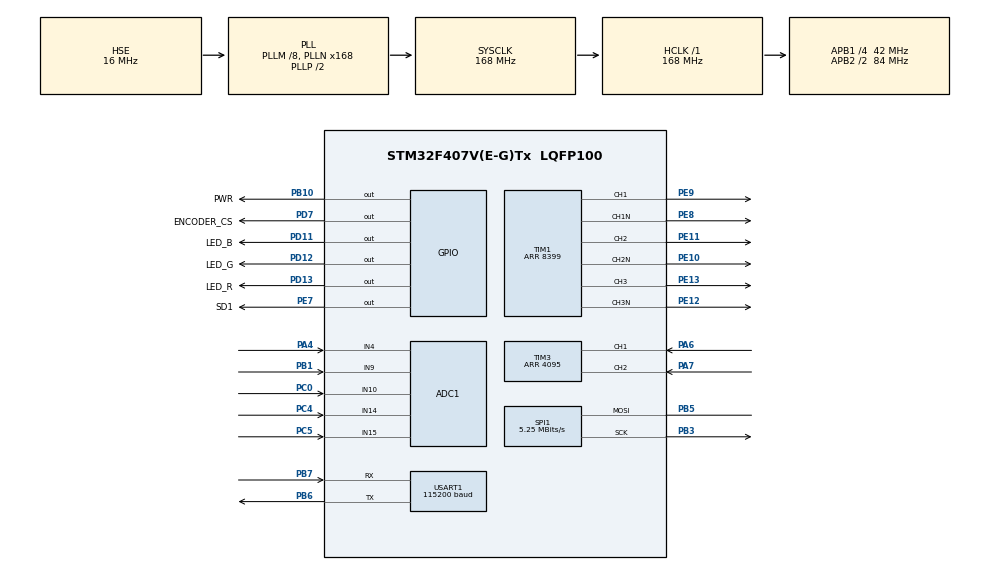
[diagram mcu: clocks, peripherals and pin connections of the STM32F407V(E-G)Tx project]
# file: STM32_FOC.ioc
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ADC1.Channel-0\#ChannelRegularConversion=ADC_CHANNEL_15
ADC1.Channel-1\#ChannelRegularConversion=ADC_CHANNEL_14
ADC1.Channel-2\#ChannelRegularConversion=ADC_CHANNEL_10
ADC1.Channel-3\#ChannelRegularConversion=ADC_CHANNEL_9
ADC1.Channel-4\#ChannelRegularConversion=ADC_CHANNEL_4
ADC1.ContinuousConvMode=ENABLE
ADC1.DMAContinuousRequests=ENABLE
ADC1.NbrOfConversion=5
ADC1.NbrOfConversionFlag=1
ADC1.Rank-0\#ChannelRegularConversion=1
ADC1.Rank-1\#ChannelRegularConversion=2
ADC1.Rank-2\#ChannelRegularConversion=3
ADC1.Rank-3\#ChannelRegularConversion=4
ADC1.Rank-4\#ChannelRegularConversion=5
ADC1.SamplingTime-0\#ChannelRegularConversion=ADC_SAMPLETIME_3CYCLES
ADC1.SamplingTime-1\#ChannelRegularConversion=ADC_SAMPLETIME_3CYCLES
ADC1.SamplingTime-2\#ChannelRegularConversion=ADC_SAMPLETIME_3CYCLES
ADC1.SamplingTime-3\#ChannelRegularConversion=ADC_SAMPLETIME_3CYCLES
ADC1.SamplingTime-4\#ChannelRegularConversion=ADC_SAMPLETIME_3CYCLES
ADC1.ScanConvMode=ENABLE
ADC1.master=1
Dma.ADC1.0.Direction=DMA_PERIPH_TO_MEMORY
Dma.ADC1.0.FIFOMode=DMA_FIFOMODE_DISABLE
Dma.ADC1.0.Instance=DMA2_Stream0
Dma.ADC1.0.MemDataAlignment=DMA_MDATAALIGN_HALFWORD
Dma.ADC1.0.MemInc=DMA_MINC_ENABLE
Dma.ADC1.0.Mode=DMA_CIRCULAR
Dma.ADC1.0.PeriphDataAlignment=DMA_PDATAALIGN_HALFWORD
Dma.ADC1.0.PeriphInc=DMA_PINC_DISABLE
Dma.ADC1.0.Priority=DMA_PRIORITY_HIGH
Dma.Request0=ADC1
Mcu.Family=STM32F4
Mcu.Name=STM32F407V(E-G)Tx
Mcu.Package=LQFP100
NVIC.PriorityGroup=NVIC_PRIORITYGROUP_4
NVIC.TIM1_UP_TIM10_IRQn=true\:0\:0\:false\:false\:true\:true\:true\:true
NVIC.TIM4_IRQn=true\:2\:0\:true\:false\:true\:true\:true\:true
NVIC.USART1_IRQn=true\:0\:0\:false\:false\:true\:true\:true\:true
PA13.Mode=Serial_Wire
PA13.Signal=SYS_JTMS-SWDIO
PA14.Mode=Serial_Wire
PA14.Signal=SYS_JTCK-SWCLK
PA4.Signal=ADCx_IN4
PA6.Signal=S_TIM3_CH1
PA7.Signal=S_TIM3_CH2
PB1.Signal=ADCx_IN9
PB10.GPIO_Label=PWR
PB10.PinState=GPIO_PIN_SET
PB10.Signal=GPIO_Output
PB3.Mode=Simplex_Bidirectional_Master
PB3.Signal=SPI1_SCK
PB4.Signal=SPI1_MISO
PB5.Mode=Simplex_Bidirectional_Master
PB5.Signal=SPI1_MOSI
PB6.Mode=Asynchronous
PB6.Signal=USART1_TX
PB7.Mode=Asynchronous
PB7.Signal=USART1_RX
PC0.Signal=ADCx_IN10
PC4.Signal=ADCx_IN14
PC5.Signal=ADCx_IN15
PD11.GPIO_Label=LED_B
PD11.PinState=GPIO_PIN_SET
PD11.Signal=GPIO_Output
PD12.GPIO_Label=LED_G
PD12.PinState=GPIO_PIN_SET
PD12.Signal=GPIO_Output
PD13.GPIO_Label=LED_R
PD13.PinState=GPIO_PIN_SET
PD13.Signal=GPIO_Output
PD7.GPIO_Label=ENCODER_CS
PD7.PinState=GPIO_PIN_SET
PD7.Signal=GPIO_Output
PE10.Mode=PWM Generation2 CH2 CH2N
PE10.Signal=TIM1_CH2N
PE11.Signal=S_TIM1_CH2
PE12.Mode=PWM Generation3 CH3 CH3N
PE12.Signal=TIM1_CH3N
PE13.Signal=S_TIM1_CH3
PE7.GPIO_Label=SD1
PE7.GPIO_Speed=GPIO_SPEED_FREQ_VERY_HIGH
PE7.Signal=GPIO_Output
PE8.Mode=PWM Generation1 CH1 CH1N
PE8.Signal=TIM1_CH1N
PE9.Signal=S_TIM1_CH1
PH0-OSC_IN.Mode=HSE-External-Oscillator
PH0-OSC_IN.Signal=RCC_OSC_IN
PH1-OSC_OUT.Mode=HSE-External-Oscillator
PH1-OSC_OUT.Signal=RCC_OSC_OUT
ProjectManager.HeapSize=0x200
ProjectManager.StackSize=0x400
ProjectManager.TargetToolchain=MDK-ARM V5.32
RCC.48MHZClocksFreq_Value=84000000
RCC.AHBFreq_Value=168000000
RCC.APB1CLKDivider=RCC_HCLK_DIV4
RCC.APB1Freq_Value=42000000
RCC.APB1TimFreq_Value=84000000
RCC.APB2CLKDivider=RCC_HCLK_DIV2
RCC.APB2Freq_Value=84000000
RCC.APB2TimFreq_Value=168000000
RCC.CortexFreq_Value=168000000
RCC.HCLKFreq_Value=168000000
RCC.HSE_VALUE=16000000
RCC.HSI_VALUE=16000000
RCC.LSE_VALUE=32768
RCC.PLLM=8
RCC.PLLN=168
RCC.PLLSourceVirtual=RCC_PLLSOURCE_HSE
RCC.SYSCLKFreq_VALUE=168000000
RCC.SYSCLKSource=RCC_SYSCLKSOURCE_PLLCLK
RCC.VCOOutputFreq_Value=336000000
SH.ADCx_IN10.0=ADC1_IN10,IN10
SH.ADCx_IN14.0=ADC1_IN14,IN14
SH.ADCx_IN15.0=ADC1_IN15,IN15
SH.ADCx_IN4.0=ADC1_IN4,IN4
SH.ADCx_IN9.0=ADC1_IN9,IN9
SH.S_TIM1_CH1.0=TIM1_CH1,PWM Generation1 CH1 CH1N
SH.S_TIM1_CH2.0=TIM1_CH2,PWM Generation2 CH2 CH2N
SH.S_TIM1_CH3.0=TIM1_CH3,PWM Generation3 CH3 CH3N
SH.S_TIM3_CH1.0=TIM3_CH1,Encoder_Interface
SH.S_TIM3_CH2.0=TIM3_CH2,Encoder_Interface
SPI1.BaudRatePrescaler=SPI_BAUDRATEPRESCALER_16
SPI1.CLKPhase=SPI_PHASE_2EDGE
SPI1.CRCCalculation=SPI_CRCCALCULATION_DISABLE
SPI1.CalculateBaudRate=5.25 MBits/s
SPI1.Direction=SPI_DIRECTION_1LINE
SPI1.Mode=SPI_MODE_MASTER
SPI1.VirtualType=VM_MASTER
TIM1.AutoReloadPreload=TIM_AUTORELOAD_PRELOAD_ENABLE
TIM1.AutomaticOutput=TIM_AUTOMATICOUTPUT_ENABLE
TIM1.Channel-PWM\ Generation1\ CH1\ CH1N=TIM_CHANNEL_1
TIM1.Channel-PWM\ Generation2\ CH2\ CH2N=TIM_CHANNEL_2
TIM1.Channel-PWM\ Generation3\ CH3\ CH3N=TIM_CHANNEL_3
TIM1.CounterMode=TIM_COUNTERMODE_CENTERALIGNED1
TIM1.DeadTime=100
TIM1.OCMode_PWM-PWM\ Generation1\ CH1\ CH1N=TIM_OCMODE_PWM2
TIM1.OCMode_PWM-PWM\ Generation2\ CH2\ CH2N=TIM_OCMODE_PWM2
TIM1.OCMode_PWM-PWM\ Generation3\ CH3\ CH3N=TIM_OCMODE_PWM2
TIM1.Period=8399
TIM3.EncoderMode=TIM_ENCODERMODE_TI12
TIM3.IC1Filter=7
TIM3.IC2Filter=7
TIM3.IC2Polarity=TIM_ICPOLARITY_FALLING
TIM3.Period=4095
TIM4.Period=999
TIM4.Prescaler=84-1
USART1.BaudRate=115200
USART1.VirtualMode=VM_ASYNC
VP_TIM1_VS_ClockSourceINT.Mode=Internal
VP_TIM4_VS_ClockSourceINT.Mode=Internal
board=custom

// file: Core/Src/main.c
/* USER CODE BEGIN Header */
/**
  ******************************************************************************
  * @file           : main.c
  * @brief          : Main program body
  ******************************************************************************
  * @attention
  *
  * Copyright (c) 2024 STMicroelectronics.
  * All rights reserved.
  *
  * This software is licensed under terms that can be found in the LICENSE file
  * in the root directory of this software component.
  * If no LICENSE file comes with this software, it is provided AS-IS.
  *
  ******************************************************************************
  */
/* USER CODE END Header */
#include "main.h"

/* USER CODE BEGIN Includes */
#include "task.h"
/* USER CODE END Includes */

ADC_HandleTypeDef hadc1;
DMA_HandleTypeDef hdma_adc1;

TIM_HandleTypeDef htim1;
TIM_HandleTypeDef htim3;
TIM_HandleTypeDef htim4;

UART_HandleTypeDef huart1;
SPI_HandleTypeDef hspi1;

void SystemClock_Config(void);
static void MX_GPIO_Init(void);
static void MX_DMA_Init(void);
static void MX_TIM4_Init(void);
static void MX_USART1_UART_Init(void);
static void MX_ADC1_Init(void);
static void MX_TIM3_Init(void);
static void MX_TIM1_Init(void);
static void MX_SPI1_Init(void);

int main(void)
{

  /* MCU Configuration--------------------------------------------------------*/

  /* Reset of all peripherals, Initializes the Flash interface and the Systick. */
  HAL_Init();

  /* Configure the system clock */
  SystemClock_Config();
  CoreDebug->DEMCR |= CoreDebug_DEMCR_TRCENA_Msk;
  DWT->CYCCNT = 0U;
  DWT->CTRL |= DWT_CTRL_CYCCNTENA_Msk;

  /* Initialize all configured peripherals */
  MX_GPIO_Init();
  MX_SPI1_Init();
  MX_DMA_Init();
  MX_TIM4_Init();
  MX_USART1_UART_Init();
  MX_ADC1_Init();
  MX_TIM3_Init();
  MX_TIM1_Init();
  /* USER CODE BEGIN 2 */
  task_init();

  /* USER CODE END 2 */

  /* Infinite loop */
  /* USER CODE BEGIN WHILE */
  while (1)
  {
      task_loop();
    /* USER CODE END WHILE */

  }
}

void SystemClock_Config(void)
{
  RCC_OscInitTypeDef RCC_OscInitStruct = {0};
  RCC_ClkInitTypeDef RCC_ClkInitStruct = {0};

  /** Configure the main internal regulator output voltage
  */
  __HAL_RCC_PWR_CLK_ENABLE();
  __HAL_PWR_VOLTAGESCALING_CONFIG(PWR_REGULATOR_VOLTAGE_SCALE1);

  /** Initializes the RCC Oscillators according to the specified parameters
  * in the RCC_OscInitTypeDef structure.
  */
  RCC_OscInitStruct.OscillatorType = RCC_OSCILLATORTYPE_HSE;
  RCC_OscInitStruct.HSEState = RCC_HSE_ON;
  RCC_OscInitStruct.PLL.PLLState = RCC_PLL_ON;
  RCC_OscInitStruct.PLL.PLLSource = RCC_PLLSOURCE_HSE;
  RCC_OscInitStruct.PLL.PLLM = 8;
  RCC_OscInitStruct.PLL.PLLN = 168;
  RCC_OscInitStruct.PLL.PLLP = RCC_PLLP_DIV2;
  RCC_OscInitStruct.PLL.PLLQ = 4;
  if (HAL_RCC_OscConfig(&RCC_OscInitStruct) != HAL_OK)
  {
    Error_Handler();
  }

  /** Initializes the CPU, AHB and APB buses clocks
  */
  RCC_ClkInitStruct.ClockType = RCC_CLOCKTYPE_HCLK|RCC_CLOCKTYPE_SYSCLK
                              |RCC_CLOCKTYPE_PCLK1|RCC_CLOCKTYPE_PCLK2;
  RCC_ClkInitStruct.SYSCLKSource = RCC_SYSCLKSOURCE_PLLCLK;
  RCC_ClkInitStruct.AHBCLKDivider = RCC_SYSCLK_DIV1;
  RCC_ClkInitStruct.APB1CLKDivider = RCC_HCLK_DIV4;
  RCC_ClkInitStruct.APB2CLKDivider = RCC_HCLK_DIV2;

  if (HAL_RCC_ClockConfig(&RCC_ClkInitStruct, FLASH_LATENCY_5) != HAL_OK)
  {
    Error_Handler();
  }
}

static void MX_ADC1_Init(void)
{

  ADC_ChannelConfTypeDef sConfig = {0};

  /** Configure the global features of the ADC (Clock, Resolution, Data Alignment and number of conversion)
  */
  hadc1.Instance = ADC1;
  hadc1.Init.ClockPrescaler = ADC_CLOCK_SYNC_PCLK_DIV4;
  hadc1.Init.Resolution = ADC_RESOLUTION_12B;
  hadc1.Init.ScanConvMode = ENABLE;
  hadc1.Init.ContinuousConvMode = ENABLE;
  hadc1.Init.DiscontinuousConvMode = DISABLE;
  hadc1.Init.ExternalTrigConvEdge = ADC_EXTERNALTRIGCONVEDGE_NONE;
  hadc1.Init.ExternalTrigConv = ADC_SOFTWARE_START;
  hadc1.Init.DataAlign = ADC_DATAALIGN_RIGHT;
  hadc1.Init.NbrOfConversion = 5;
  hadc1.Init.DMAContinuousRequests = ENABLE;
  hadc1.Init.EOCSelection = ADC_EOC_SINGLE_CONV;
  if (HAL_ADC_Init(&hadc1) != HAL_OK)
  {
    Error_Handler();
  }

  /** Configure for the selected ADC regular channel its corresponding rank in the sequencer and its sample time.
  */
  sConfig.Channel = ADC_CHANNEL_15;
  sConfig.Rank = 1;
  sConfig.SamplingTime = ADC_SAMPLETIME_3CYCLES;
  if (HAL_ADC_ConfigChannel(&hadc1, &sConfig) != HAL_OK)
  {
    Error_Handler();
  }

  /** Configure for the selected ADC regular channel its corresponding rank in the sequencer and its sample time.
  */
  sConfig.Channel = ADC_CHANNEL_14;
  sConfig.Rank = 2;
  if (HAL_ADC_ConfigChannel(&hadc1, &sConfig) != HAL_OK)
  {
    Error_Handler();
  }

  /** Configure for the selected ADC regular channel its corresponding rank in the sequencer and its sample time.
  */
  sConfig.Channel = ADC_CHANNEL_10;
  sConfig.Rank = 3;
  if (HAL_ADC_ConfigChannel(&hadc1, &sConfig) != HAL_OK)
  {
    Error_Handler();
  }

  /** Configure for the selected ADC regular channel its corresponding rank in the sequencer and its sample time.
  */
  sConfig.Channel = ADC_CHANNEL_9;
  sConfig.Rank = 4;
  if (HAL_ADC_ConfigChannel(&hadc1, &sConfig) != HAL_OK)
  {
    Error_Handler();
  }

  /** Configure for the selected ADC regular channel its corresponding rank in the sequencer and its sample time.
  */
  sConfig.Channel = ADC_CHANNEL_4;
  sConfig.Rank = 5;
  if (HAL_ADC_ConfigChannel(&hadc1, &sConfig) != HAL_OK)
  {
    Error_Handler();
  }

}

static void MX_TIM1_Init(void)
{

  TIM_ClockConfigTypeDef sClockSourceConfig = {0};
  TIM_MasterConfigTypeDef sMasterConfig = {0};
  TIM_OC_InitTypeDef sConfigOC = {0};
  TIM_BreakDeadTimeConfigTypeDef sBreakDeadTimeConfig = {0};

  htim1.Instance = TIM1;
  htim1.Init.Prescaler = 0;
  htim1.Init.CounterMode = TIM_COUNTERMODE_CENTERALIGNED1;
  htim1.Init.Period = 8399;
  htim1.Init.ClockDivision = TIM_CLOCKDIVISION_DIV1;
  htim1.Init.RepetitionCounter = 0;
  htim1.Init.AutoReloadPreload = TIM_AUTORELOAD_PRELOAD_ENABLE;
  if (HAL_TIM_Base_Init(&htim1) != HAL_OK)
  {
    Error_Handler();
  }
  sClockSourceConfig.ClockSource = TIM_CLOCKSOURCE_INTERNAL;
  if (HAL_TIM_ConfigClockSource(&htim1, &sClockSourceConfig) != HAL_OK)
  {
    Error_Handler();
  }
  if (HAL_TIM_PWM_Init(&htim1) != HAL_OK)
  {
    Error_Handler();
  }
  sMasterConfig.MasterOutputTrigger = TIM_TRGO_RESET;
  sMasterConfig.MasterSlaveMode = TIM_MASTERSLAVEMODE_DISABLE;
  if (HAL_TIMEx_MasterConfigSynchronization(&htim1, &sMasterConfig) != HAL_OK)
  {
    Error_Handler();
  }
  sConfigOC.OCMode = TIM_OCMODE_PWM2;
  sConfigOC.Pulse = 0;
  sConfigOC.OCPolarity = TIM_OCPOLARITY_HIGH;
  sConfigOC.OCNPolarity = TIM_OCNPOLARITY_HIGH;
  sConfigOC.OCFastMode = TIM_OCFAST_DISABLE;
  sConfigOC.OCIdleState = TIM_OCIDLESTATE_RESET;
  sConfigOC.OCNIdleState = TIM_OCNIDLESTATE_RESET;
  if (HAL_TIM_PWM_ConfigChannel(&htim1, &sConfigOC, TIM_CHANNEL_1) != HAL_OK)
  {
    Error_Handler();
  }
  if (HAL_TIM_PWM_ConfigChannel(&htim1, &sConfigOC, TIM_CHANNEL_2) != HAL_OK)
  {
    Error_Handler();
  }
  if (HAL_TIM_PWM_ConfigChannel(&htim1, &sConfigOC, TIM_CHANNEL_3) != HAL_OK)
  {
    Error_Handler();
  }
  sBreakDeadTimeConfig.OffStateRunMode = TIM_OSSR_DISABLE;
  sBreakDeadTimeConfig.OffStateIDLEMode = TIM_OSSI_DISABLE;
  sBreakDeadTimeConfig.LockLevel = TIM_LOCKLEVEL_OFF;
  sBreakDeadTimeConfig.DeadTime = 100;
  sBreakDeadTimeConfig.BreakState = TIM_BREAK_DISABLE;
  sBreakDeadTimeConfig.BreakPolarity = TIM_BREAKPOLARITY_HIGH;
  sBreakDeadTimeConfig.AutomaticOutput = TIM_AUTOMATICOUTPUT_ENABLE;
  if (HAL_TIMEx_ConfigBreakDeadTime(&htim1, &sBreakDeadTimeConfig) != HAL_OK)
  {
    Error_Handler();
  }
  HAL_TIM_MspPostInit(&htim1);

}

static void MX_TIM3_Init(void)
{

  TIM_Encoder_InitTypeDef sConfig = {0};
  TIM_MasterConfigTypeDef sMasterConfig = {0};

  htim3.Instance = TIM3;
  htim3.Init.Prescaler = 0;
  htim3.Init.CounterMode = TIM_COUNTERMODE_UP;
  htim3.Init.Period = 4095;
  htim3.Init.ClockDivision = TIM_CLOCKDIVISION_DIV1;
  htim3.Init.AutoReloadPreload = TIM_AUTORELOAD_PRELOAD_DISABLE;
  sConfig.EncoderMode = TIM_ENCODERMODE_TI12;
  sConfig.IC1Polarity = TIM_ICPOLARITY_RISING;
  sConfig.IC1Selection = TIM_ICSELECTION_DIRECTTI;
  sConfig.IC1Prescaler = TIM_ICPSC_DIV1;
  sConfig.IC1Filter = 7;
  sConfig.IC2Polarity = TIM_ICPOLARITY_FALLING;
  sConfig.IC2Selection = TIM_ICSELECTION_DIRECTTI;
  sConfig.IC2Prescaler = TIM_ICPSC_DIV1;
  sConfig.IC2Filter = 7;
  if (HAL_TIM_Encoder_Init(&htim3, &sConfig) != HAL_OK)
  {
    Error_Handler();
  }
  sMasterConfig.MasterOutputTrigger = TIM_TRGO_RESET;
  sMasterConfig.MasterSlaveMode = TIM_MASTERSLAVEMODE_DISABLE;
  if (HAL_TIMEx_MasterConfigSynchronization(&htim3, &sMasterConfig) != HAL_OK)
  {
    Error_Handler();
  }

}

static void MX_TIM4_Init(void)
{

  TIM_ClockConfigTypeDef sClockSourceConfig = {0};
  TIM_MasterConfigTypeDef sMasterConfig = {0};

  htim4.Instance = TIM4;
  htim4.Init.Prescaler = 84-1;
  htim4.Init.CounterMode = TIM_COUNTERMODE_UP;
  htim4.Init.Period = 999;
  htim4.Init.ClockDivision = TIM_CLOCKDIVISION_DIV1;
  htim4.Init.AutoReloadPreload = TIM_AUTORELOAD_PRELOAD_DISABLE;
  if (HAL_TIM_Base_Init(&htim4) != HAL_OK)
  {
    Error_Handler();
  }
  sClockSourceConfig.ClockSource = TIM_CLOCKSOURCE_INTERNAL;
  if (HAL_TIM_ConfigClockSource(&htim4, &sClockSourceConfig) != HAL_OK)
  {
    Error_Handler();
  }
  sMasterConfig.MasterOutputTrigger = TIM_TRGO_RESET;
  sMasterConfig.MasterSlaveMode = TIM_MASTERSLAVEMODE_DISABLE;
  if (HAL_TIMEx_MasterConfigSynchronization(&htim4, &sMasterConfig) != HAL_OK)
  {
    Error_Handler();
  }

}

static void MX_USART1_UART_Init(void)
{

  huart1.Instance = USART1;
  huart1.Init.BaudRate = 115200;
  huart1.Init.WordLength = UART_WORDLENGTH_8B;
  huart1.Init.StopBits = UART_STOPBITS_1;
  huart1.Init.Parity = UART_PARITY_NONE;
  huart1.Init.Mode = UART_MODE_TX_RX;
  huart1.Init.HwFlowCtl = UART_HWCONTROL_NONE;
  huart1.Init.OverSampling = UART_OVERSAMPLING_16;
  if (HAL_UART_Init(&huart1) != HAL_OK)
  {
    Error_Handler();
  }

}

static void MX_DMA_Init(void)
{

  /* DMA controller clock enable */
  __HAL_RCC_DMA2_CLK_ENABLE();

}

static void MX_GPIO_Init(void)
{
  GPIO_InitTypeDef GPIO_InitStruct = {0};

  /* GPIO Ports Clock Enable */
  __HAL_RCC_GPIOH_CLK_ENABLE();
  __HAL_RCC_GPIOC_CLK_ENABLE();
  __HAL_RCC_GPIOA_CLK_ENABLE();
  __HAL_RCC_GPIOB_CLK_ENABLE();
  __HAL_RCC_GPIOE_CLK_ENABLE();
  __HAL_RCC_GPIOD_CLK_ENABLE();

  /*Configure GPIO pin Output Level */
  HAL_GPIO_WritePin(SD1_GPIO_Port, SD1_Pin, GPIO_PIN_RESET);

  /*Configure GPIO pin Output Level */
  HAL_GPIO_WritePin(PWR_GPIO_Port, PWR_Pin, GPIO_PIN_SET);

  /*Configure GPIO pin Output Level */
  HAL_GPIO_WritePin(GPIOD, LED_B_Pin|LED_G_Pin|LED_R_Pin, GPIO_PIN_SET);

  /*Configure encoder chip select as inactive before enabling SPI */
  HAL_GPIO_WritePin(ENCODER_CS_GPIO_Port, ENCODER_CS_Pin, GPIO_PIN_SET);

  /*Configure GPIO pin : SD1_Pin */
  GPIO_InitStruct.Pin = SD1_Pin;
  GPIO_InitStruct.Mode = GPIO_MODE_OUTPUT_PP;
  GPIO_InitStruct.Pull = GPIO_NOPULL;
  GPIO_InitStruct.Speed = GPIO_SPEED_FREQ_VERY_HIGH;
  HAL_GPIO_Init(SD1_GPIO_Port, &GPIO_InitStruct);

  /*Configure GPIO pin : PWR_Pin */
  GPIO_InitStruct.Pin = PWR_Pin;
  GPIO_InitStruct.Mode = GPIO_MODE_OUTPUT_PP;
  GPIO_InitStruct.Pull = GPIO_NOPULL;
  GPIO_InitStruct.Speed = GPIO_SPEED_FREQ_LOW;
  HAL_GPIO_Init(PWR_GPIO_Port, &GPIO_InitStruct);

  /*Configure GPIO pins : LED_B_Pin LED_G_Pin LED_R_Pin */
  GPIO_InitStruct.Pin = LED_B_Pin|LED_G_Pin|LED_R_Pin;
  GPIO_InitStruct.Mode = GPIO_MODE_OUTPUT_PP;
  GPIO_InitStruct.Pull = GPIO_NOPULL;
  GPIO_InitStruct.Speed = GPIO_SPEED_FREQ_LOW;
  HAL_GPIO_Init(GPIOD, &GPIO_InitStruct);

  GPIO_InitStruct.Pin = ENCODER_CS_Pin;
  GPIO_InitStruct.Mode = GPIO_MODE_OUTPUT_PP;
  GPIO_InitStruct.Pull = GPIO_NOPULL;
  GPIO_InitStruct.Speed = GPIO_SPEED_FREQ_VERY_HIGH;
  HAL_GPIO_Init(ENCODER_CS_GPIO_Port, &GPIO_InitStruct);

}

static void MX_SPI1_Init(void)
{
  hspi1.Instance = SPI1;
  hspi1.Init.Mode = SPI_MODE_MASTER;
  hspi1.Init.Direction = SPI_DIRECTION_1LINE;
  hspi1.Init.DataSize = SPI_DATASIZE_8BIT;
  hspi1.Init.CLKPolarity = SPI_POLARITY_LOW;
  hspi1.Init.CLKPhase = SPI_PHASE_2EDGE;
  hspi1.Init.NSS = SPI_NSS_SOFT;
  /* APB2 is 84 MHz; /16 keeps the encoder transfer short within the FOC period. */
  hspi1.Init.BaudRatePrescaler = SPI_BAUDRATEPRESCALER_16;
  hspi1.Init.FirstBit = SPI_FIRSTBIT_MSB;
  hspi1.Init.TIMode = SPI_TIMODE_DISABLE;
  hspi1.Init.CRCCalculation = SPI_CRCCALCULATION_DISABLE;
  hspi1.Init.CRCPolynomial = 10;
  if (HAL_SPI_Init(&hspi1) != HAL_OK)
  {
    Error_Handler();
  }
}

void Error_Handler(void)
{
  __disable_irq();
  while (1)
  {
  }
}
